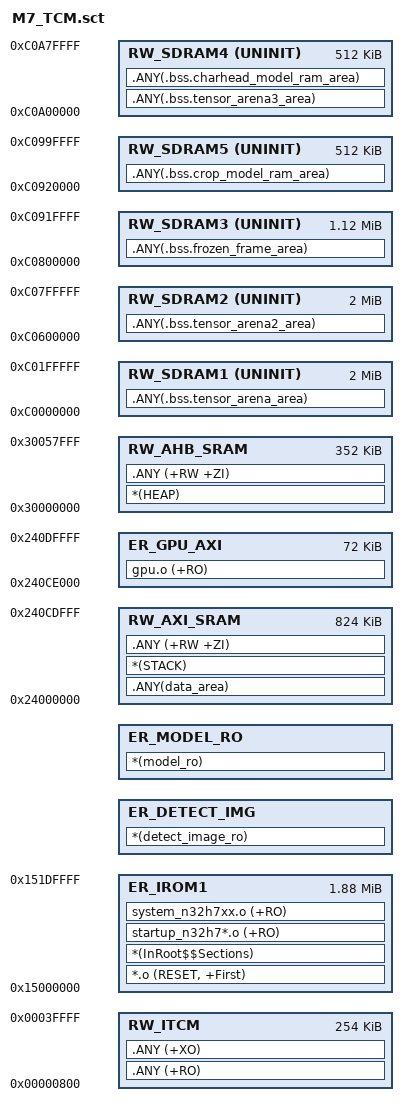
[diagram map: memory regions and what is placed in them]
; *************************************************************
; *** Scatter-Loading Description File generated by uVision ***
; *************************************************************
; N32H787xIx7:CM7 - WARNING: the ITCM / DTCM / AXI_SRAM2-3 split of the 1MB TCM
; block is NOT fixed hardware.  It is stored in OTP and selected by TCM_SIZE_VALUE
; in firmware\CMSIS\device\system_n32h7xx.c.  The value compiled in right now is:
;
;     #define TCM_SIZE_VALUE   (0x27)
;
; The table above ConfigTcmSize() (system_n32h7xx.c:113) has one row per value
; PER CHIP FAMILY, and 0x27 does not mean the same thing in two of them.  For
; N32H78x - this part - it is:
;
;     0x27 : 256 KB ITCM, 0 KB DTCM, 768 KB AXI_SRAM2/3, 128 KB AXI SRAM1
;
; while the N32H73x row for the same 0x27 says 384 KB of AXI_SRAM2/3.  An
; earlier version of this comment quoted the N32H73x row, which is where the
; 512K for RW_AXI_SRAM below used to come from - 384 KB short of what this part
; has, and the reason for the warning above.
;
; So the memory that physically exists with this setting is:
;   ITCM       0x00000000   256K   (vector table occupies 0x00000..0x007FF)
;   DTCM       0x20000000     0K   <-- DOES NOT EXIST, never place anything here
;   AXI SRAM   0x24000000   896K   (SRAM1 128K + SRAM2/3 768K)
;   AHB SRAM   0x30000000   352K   (0x30000000..0x30058000)
;   XIP flash  0x15000000  1.875M
;   SDRAM      0xC0000000    32M   (external, FEMC - the board is
;                                   SDRAM_IS42S32800J_HMI, AddrMask 0xFE000000.
;                                   The regions below claim 0xC0000000..0xC0B00000
;                                   only, which is deliberate; the camera's two
;                                   frame buffers and the GPU's slot sit inside
;                                   that span at raw addresses from inc/bsp_dvp.h
;                                   and inc/gpu.h.  The full map, and why the
;                                   bases are where they are, is written out at
;                                   RW_SDRAM1 near the end of this file)
;
; THE NUMBERS ABOVE ARE MEASURED ON THIS BOARD, not assumed.  They have to be
; measured, because that split is not fixed hardware: ConfigTcmSize()
; (system_n32h7xx.c:177) programs the OTP only when the register reads back
; 0x2C - i.e. never programmed - and it is written once per part, not per image.
; So a part that has run a vendor example first holds whatever that example
; asked for, and the 0x27 this build requests is then a silent no-op.  Nothing
; in a build says which way that went.
;
; gpu_tcm_probe() reads the OTP back at boot.  On 2026-09-15 it read
; 0x00000027, which is what the table above says this build asks for, so the
; two agree and the numbers above are the real ones.  That is what let
; RW_AXI_SRAM below grow from 512K to the full 896K.
;
; AHB SRAM is not one block either: it is AHBSRAM1..AHBSRAM5S2, six banks with
; independent power gates and retention controls (PWR_SYSMEMLPCTRL_AHBSRAM*_PG,
; *_RET1N, *_RET2N - n32h7xx.h:8302+).
;
;     0x30000000  SRAM1  128K   ┐
;     0x30020000  SRAM2  128K   ├ written every frame by the camera, so proven
;     0x30040000  SRAM3   32K   │ good on this board
;     0x30048000  SRAM4   32K   ┘
;     0x30050000  SRAM5b1 16K   ┐ nothing else on this board writes these
;     0x30054000  SRAM5b2 16K   ┘
;
; *(HEAP) is the reason this matters.  It used to start in SRAM4 and run out of
; SRAM5b2 - two banks nothing else on this board writes, which is a bad place to
; put the allocator on a board that has never proved them.  It now sits wholly
; inside SRAM1, the bank the camera writes every frame.
;
; Nothing below asks the hardware for that, and no line here says where the heap
; goes: it is a consequence of the globals no longer competing for
; RW_AHB_SRAM, so it is re-derived on every link.  After any change to either
; region, look it up in Printf.map and check it is still inside
; 0x30000000..0x30020000 - the map prints it as an unnamed
;
;     0x3000....        -       0x00008000   Zero   RW   2   HEAP  startup_n32h78x_cm7.o
;
; section (the label Heap_Mem is not exported, so only the section shows).
;
; Every vendor GPU example runs without complaint while using AHB SRAM for
; nothing but a small texture buffer at 0x30000000, keeping its heap in DTCM /
; AXI SRAM; this build keeps its C library heap in AHB SRAM instead, which is
; the one structural difference between the two.
;
; If TCM_SIZE_VALUE is ever changed, this file must change with it.
; armlink trusts the numbers below and cannot see the silicon: an over-sized
; region links cleanly with 0 errors and only faults on the board.
;
; History: a RW_DTCM 0x20000000 0x00080000 region was tried here and hung before
; main() - with TCM_SIZE_VALUE=0x27 DTCM is 0K, so the startup copy of the model
; and the stack went into unmapped space.

; Raised from 1MB to the part's full 1.875M (the header comment above).  1MB was
; 93.7% full: the map of the 2026-10-13 build reads
;
;     Load Region LR_IROM1 (Base: 0x15000000, Size: 0x000efd68, Max: 0x00100000
;
; 982,376 of 1,048,576 bytes - 66K free, and the two extra int8 models Phase 1
; adds are 431,360 + 90,144 = 521,504.  So this is not headroom, it is the
; change that makes ER_MODEL_RO placeable at all.
LR_IROM1 0x15000000 0x001E0000  {    ; load region size_region
  ; This Max only matches the load region; it is NOT the binding ceiling, and
  ; the earlier note in this file that called it one was wrong.  ER_IROM1 holds
  ; 0x2160 (8,544) bytes of vector table and startup code, and armlink places
  ; the next region after a region's *actual* size, not after its Max: the map
  ; above puts ER_DETECT_IMG at 0x15002160 = 0x15000000 + 0x2160.  Left at
  ; 0x00100000 this would link exactly the same.  Raised anyway, because a Max
  ; that does not mean what it looks like is a trap, and the day something does
  ; grow into ER_IROM1 the gap between these two lines surfaces as an L6220E
  ; naming the wrong region.
  ER_IROM1 0x15000000 0x001E0000  {  ; load address = execution address
   *.o (RESET, +First)
   *(InRoot$$Sections)
   startup_n32h7*.o (+RO)
   system_n32h7xx.o (+RO)
  }

  ; 320x320 RGB888 detection frame (src/yolo_detect_image.inc), 307,200 bytes,
  ; read in place out of XIP flash.  It must NOT be left to .ANY (+RO): that
  ; lands in ITCM, which only has ~117K free, so a 300K array would fail to
  ; place.  +0 puts it right after ER_IROM1 and ahead of the RW init copies, and
  ; armlink moves those up as needed.
  ER_DETECT_IMG +0  {
   *(detect_image_ro)
  }

  ; The ② crop detector and ③ char classifier int8 models (inc/model_data_crop.h
  ; and inc/model_data_charhead.h), 431,360 + 90,144 = 521,504 bytes.
  ;
  ; Stored here rather than in ①'s data_area because AXI SRAM has only ~114K
  ; spare once ① takes 431K of its 896K, and ② alone is 431,360 bytes.
  ;
  ; Read in place over the XIP bus was the original plan and is NOT what the
  ; firmware does: both are copied into SDRAM at init, with the D-cache off,
  ; and parsed from that copy.  The reason is the ② anomaly (one 32-byte row of
  ; the 431,360 read back as the file's bytes from +16); until its cause is
  ; known, the weights are not read out of flash at run time at all.  What this
  ; region decides is only where the bytes are *stored*, and both headers carry
  ; section("model_ro") - not ①'s section("data_area"), which __main copies to
  ; AXI SRAM before SDRAM exists.
  ;
  ; Placed with the detect image, before the RW init copies, so the model blobs
  ; sit together at the bottom of the flash.  This only picks the layout - what
  ; decides whether it fits is the load region above, 0x001E0000, and the weights
  ; are incompressible so armlink's compression saves almost nothing on them.
  ;
  ; Alignment: the arrays in here carry aligned(32) (see the ALIGN paragraph in
  ; tflite/export_c_array.py, and the long note above yolo_cascade_init() in
  ; MDK-ARM/yolo_inference.cpp), so armlink lifts this region's base to a 32-byte
  ; boundary.  It used to sit at 0x1504d110 - 16-aligned, not 32 - and the only
  ; wrong bytes the board ever read out of the 431,360 were exactly the first
  ; full 32-byte line of it.  Check the new address in Printf.map after linking.
  ER_MODEL_RO +0  {
   *(model_ro)
  }

  ;ITCM 256K, offset 0x400 for VECTOR TABLE
  RW_ITCM 0x00000800 0x0003F800  {
   .ANY (+RO)
   .ANY (+XO)
  }

  ; AXI SRAM 0x24000000 + 896K, which is everything the part has under 0x27
  ; (AXI_SRAM1 0x24000000 128K + AXI_SRAM2 0x24020000 512K + AXI_SRAM3
  ; 0x240A0000 256K, from n32h7xx_eccmon.h:81-83, contiguous).  It was 512K
  ; until gpu_tcm_probe() read the OTP back and confirmed 0x27 on this board;
  ; see the header comment.
  ;
  ; Holds everything that is not read-only: the 431KB yolo int8 model - __main
  ; copies it out of XIP flash at startup, so nothing reads the weights over the
  ; XIP bus at run time any more - the main stack, and now the RW/ZI globals too.
  ;
  ; .ANY (+RW +ZI) was commented out while the region was 512K, because
  ; 431,360 (model) + 65,536 (stack) = 496,896 left only ~27K and the rest had
  ; to go somewhere.  That is why ~337K of this firmware's state ended up in
  ; AHB SRAM, pressed right up against the C library heap - and an overrunning
  ; global there silently corrupts the allocator instead of failing loudly,
  ; which is what cost a long session on the GPU bring-up.  With the full 896K
  ; the globals fit here and that pressure is gone.  What still lands in AHB
  ; SRAM is a few KB at the bottom of the region; the heap sits ~5K above it
  ; and is no longer the neighbour of anything large.
  ;
  ; Max is 0x000CE000, not the full 0x000E0000: the top 0x12000 (72 KB) is
  ; handed to ER_GPU_AXI just below, which is what makes GPU_ENABLE=1 link
  ; again.  Shrinking Max does not move the base, and armlink's .ANY choice
  ; does not depend on Max, so nothing in this region should have moved - but
  ; check it: the map's RW_AXI_SRAM Size must still read 0x000c4500 (803,072,
  ; measured 2026-10-16).  If it changed, something got pushed into AHB SRAM.
  RW_AXI_SRAM 0x24000000 0x000CE000  {
   .ANY(data_area)
   *(STACK)
   .ANY (+RW +ZI)
  }

  ; ---------------------------------------------------------------------------
  ; gpu.c's read-only content - its code and its own rodata, 33,157 bytes
  ; (Code 27,648 + RO 5,509, the Image component sizes table in Printf.map).
  ; It lives in AXI SRAM rather than ITCM so that GPU_ENABLE=1 and the
  ; three-network cascade can be in one image.
  ;
  ; THE PROBLEM IT SOLVES.  Turning GPU_ENABLE back on on 2026-10-16 failed to
  ; link: 484 x L6406E, every one of them a read-only section, zero RW/ZI - so
  ; exactly one execution region was full, and the only region in this file
  ; that takes .text/.rodata at all is RW_ITCM's `.ANY (+RO)` above.  Measured
  ; by relinking with that region's Max inflated: RW_ITCM needs 0x40500
  ; (263,424) and has 0x3F800 (260,096) - short by 3,328 bytes.  Nothing else
  ; is close: flash has 424 KB spare, RW_AXI_SRAM 111 KB, RW_AHB_SRAM 191 KB.
  ; Both halves of that were in the budget already: the GPU build needed
  ; ~237,388 of ITCM and had ~22.7 KB spare before the cascade, and the
  ; cascade adds 26,036 (Code +21,072, rodata +4,964).
  ;
  ; WHY AXI SRAM AND NOT XIP FLASH.  XIP is the obvious home for "cold" code -
  ; ER_DETECT_IMG right above reads in place out of it - but it is also the
  ; read path that returned one 32-byte row of ②'s weights wrong, and whose
  ; cause is still open (see the RW_SDRAM5 block and the note above
  ; yolo_cascade_init()).  A wrong *pixel* is one wrong character; a wrong
  ; *instruction fetch* is a board that runs off into nothing.  AXI SRAM is
  ; internal, the same reliability class as ITCM, I-cached like anything else,
  ; and 0x240CE000 is already inside the SRAM3 territory RW_AXI_SRAM has been
  ; using up to 0x240C4500 for a day.
  ;
  ; WHY ONLY gpu.o.  It is the largest item that is ours to move (33,157) and
  ; the shortfall is 3,328.  The DAVE HD driver stays in ITCM: it comes out of
  ; nsgpu.lib, and naming a library member in a scatter region force-extracts
  ; it, so moving it would drag the whole kernel into builds that do not
  ; reference it.  gpu.o is an ordinary object file, and an explicit selector
  ; for a *removed* section does not bring it back - measured 2026-10-16 with
  ; mock_micro_graph.o, which stayed removed and left the image byte-identical.
  ;
  ; WHAT THAT MEANS AT GPU_ENABLE=0.  The region's selector matches only
  ; sections that --remove has already dropped, so armlink reports
  ;
  ;     Warning: L6329W: Pattern gpu.o(RO) only matches removed unused sections.
  ;
  ; and the image is exactly what it was before this region existed.  That
  ; warning is expected in a GPU_ENABLE=0 build, not a symptom.  It is the one
  ; build-time trace of a region that exists to serve the other build.
  ;
  ; Nothing needs an MPU region for this.  main.c programs regions 0/1/3/4/5,
  ; all in SDRAM, and calls MPU_Enable(MPU_PRIVILEGED_DEFAULT) - so this falls
  ; back to the default memory map, which marks 0x20000000..0x3FFFFFFF Normal,
  ; cacheable and executable.  That is the same reason the rest of AXI SRAM
  ; (the stack, the globals) works without a region of its own.
  ; ---------------------------------------------------------------------------
  ER_GPU_AXI 0x240CE000 0x00012000  {
   gpu.o (+RO)
  }

  ; AHB SRAM 0x30000000 + 352K - the spillover region, and the home of the C
  ; library heap.  Most of it is now unused: RW_AXI_SRAM above took the globals,
  ; so this holds *(HEAP) plus the few KB of sections armlink's .ANY placement
  ; chose to put here.  That is fine - the point of the change is which bank the
  ; heap lands in, not how full this region is; see the header comment.
  RW_AHB_SRAM 0x30000000 0x00058000  {
   *(HEAP)
   .ANY (+RW +ZI)
  }

  ; yolo-320 int8: tensor arena -> external SDRAM 0xC0000000 (FEMC).
  ; UNINIT: SDRAM not ready during startup, so it must NOT be zero-initialised.
  ; The section is emitted as ZI (SHT_NOBITS) only because its name starts with
  ; ".bss." (Arm Compiler 6); a plain name would become RW and get copied by
  ; __main before SDRAM init -> HardFault before main.
  ;
  ; 2MB, not the full 8MB: the camera needs TWO 800x480 RGB565 frame buffers and
  ; there is no SRAM big enough for even one, so everything above the arena is
  ; handed to it at CAM_FRAME_BUFFER_ADDRESS / CAM_FRAME_BUFFER2_ADDRESS =
  ; 0xC0200000 / 0xC02BB800 (inc/bsp_dvp.h).  The two numbers are one decision -
  ; changing either means changing both.
  ;
  ; 2MB is not a guess: yolo_plate_init() prints arena_used_bytes() and the board
  ; reports 1,303,080 bytes used, so this leaves ~790KB spare.  It was 7.25MB
  ; while there was only one frame buffer; the second one is what bought the
  ; shrink (one frame buffer does not fit in the 30KB that was left over).
  ;
  ; RW_SDRAM2/3/4 at the end of this file continue this layout; read the block
  ; comment there before moving anything.
  RW_SDRAM1 0xC0000000 UNINIT 0x00200000  {  ; 2 MB tensor arena
   .ANY(.bss.tensor_arena_area)
  }

  ; ---------------------------------------------------------------------------
  ; The rest of SDRAM, 0xC0200000 up to 0xC0C00000.  It is one decision spread
  ; over four files - this one, inc/bsp_dvp.h, inc/gpu.h and the MPU table in
  ; src/main.c - so the whole layout is written out here.  Nothing allocates;
  ; every address is raw:
  ;
  ;   0xC0000000  RW_SDRAM1          2MB    ① tensor arena            (here)
  ;   0xC0200000  CAM_FRAME_BUFFER         800x480 RGB565, ping-pong   (bsp_dvp.h)
  ;   0xC02BB800  CAM_FRAME_BUFFER2        second half of that pair
  ;   0xC0377000  <- the two frame buffers end here (src/camera.c:512 agrees;
  ;                  the 0xC0371000 in src/main.c's region-1 comment does not,
  ;                  it is a digit short - 2 x 768,000 = 0x177000)
  ;   0xC0380000  CAM_ALT_BUF
  ;   0xC03D0000  <- crop_fill_neigh() paints 192K up to here (gpu.c:3586)
  ;   0xC0400000  GPU_CROP_SRC             GPU crop source            (gpu.h)
  ;   0xC04BB800  <- same function paints 264K from here, i.e. from
  ;                  CROP_SRC + CROP_PITCH*CROP_PROD_H*2 = +800*480*2 (gpu.c:3587)
  ;   0xC053F800  <- and ends here.  This is the highest address any GPU crop
  ;                  write reaches; everything between it and 0xC0C00000 is free
  ;   0xC0600000  RW_SDRAM2          2MB    ② tensor arena            (here)
  ;   0xC0800000  RW_SDRAM3       1.099MB  frozen 800x480 RGB888 frame (here)
  ;   0xC0A00000  RW_SDRAM4        512K    ③ arena + weight copy     (here)
  ;   0xC0C00000  GPU_SLOT_BASE       4MB    GPU slot                  (gpu.h)
  ;   0xC0E00000  GPU_DW_SRC / 0xC0FC0000 GPU_SCALE_DST
  ;
  ; Every base below is a multiple of 2MB, and that is not tidiness.  An MPU
  ; region must be a power of two long and aligned to its own length, so a 2MB
  ; region can only start at 0xC0600000, 0xC0800000 or 0xC0A00000.  The frame
  ; buffers and 0xC053F800 are not usable bases at all, which is what puts the
  ; first of the three 786K past the GPU crop's high-water mark rather than
  ; wherever it would be tidier to start.
  ;
  ; None of them may reach 0xC0C00000 either.  src/main.c makes these regions
  ; cacheable, and 0xC0C00000-on must stay uncacheable Device memory: make the
  ; GPU slot cacheable and CPU writes to GPU_CROP_SRC sit in the D-cache while
  ; the GPU DMAs memory, so the next read returns stale pixels - and this board
  ; has no cache maintenance call to fix that mid-transfer.  That is the whole
  ; reason there are three regions here and not one 8MB region at 0xC0400000.
  ;
  ; UNINIT on all three, like RW_SDRAM1: SDRAM is not ready during startup and
  ; must not be zero-initialised or copied into.  Each section name starts with
  ; ".bss." so Arm Compiler 6 emits it as ZI/SHT_NOBITS; a plain name makes it
  ; RW, and __main then copies it before SDRAM init -> HardFault before main().
  ; ---------------------------------------------------------------------------

  ; ② tensor arena.  2MB for the same reason RW_SDRAM1 is 2MB: ② has ①'s exact
  ; architecture - same 85-channel layout, same two heads, same 20x20 + 10x10
  ; grids - so it needs the same arena, and ① measured 1,303,080 bytes used.
  ; 1.5MB would do; 2MB costs nothing here and keeps the two regions identical
  ; to reason about.
  RW_SDRAM2 0xC0600000 UNINIT 0x00200000  {
   .ANY(.bss.tensor_arena2_area)
  }

  ; The frozen full-resolution camera frame: 800x480 RGB888 = 1,152,000 =
  ; 0x119400 bytes, rounded up to 0x120000.  (Not 1,125,000 - that arithmetic
  ; slip is 25,600 bytes short and would have failed as an L6220E.)
  ;
  ; src/main.c's MPU region 4 covers this with a 2 MB region, which is the only
  ; size an MPU region starting at 0xC0800000 can be.  The region is therefore
  ; 0xC0800000..0xC09FFFFF and the 0xAC000 of slack here is unusable by anything
  ; else - do not move RW_SDRAM4 down into it.
  ;
  ; Freezing the frame is required, not an optimisation.  The ping-pong buffers
  ; flip every ~66ms while one 320x320 inference takes 1.7-4.6s, so ② calling
  ; camera_frame_addr() again would crop a different picture than the one ①'s
  ; box came from - a silent, plausible-looking wrong answer.  The address is
  ; pinned once, unpacked here, and ②/③ derive from this copy only.
  RW_SDRAM3 0xC0800000 UNINIT 0x00120000  {
   .ANY(.bss.frozen_frame_area)
  }

  ; ② 的模型副本: XIP flash 里的 g_model_crop 拷进来的那份 (见
  ; MDK-ARM/yolo_inference.cpp 里 yolo_cascade_init() 顶上那段长的)。
  ;
  ; 为什么需要它: 上板在 TFLM 的 StartModelAllocation 里崩了, 反汇编钉到
  ; `LDRH r1,[vtable,#8]` 读回了 0xEA2C —— 而文件里那个位置是 20 (根表才 32
  ; 字节, 合法字段偏移到不了 59948)。 也就是 ② 从 XIP 读到的字节和文件不是同一份。
  ; 2026-10-16 量出来的形状: 板子读到的 431,360 字节和文件只差**一条 32 字节
  ; 行** (rel 0x10..0x2F), 装的是文件 +16 处的内容; 而磁盘上那个镜像逐字节
  ; 是对的 (tflite/_dbg_image.py 比过), 也不是读宽度 (32/16/8 位四个 CRC 全等)。
  ; 所以先按 ① 的办法办, 只是目的地换成 SDRAM; 而且拷贝那一遍放在关掉 D-Cache 的
  ; 区间里做 —— 关着读和开着读的 CRC32 都打出来, 这一对数就是
  ; "CPU 读通路" 和 "flash 内容不对" 的分界。 详见 yolo_cascade_init() 顶上那段。
  ;
  ; 0xC0920000 = RW_SDRAM3 的 Max 末尾 (0xC0800000 + 0x120000), 所以它既在
  ; MPU region 4 (0xC0800000, 2MB, WB cacheable) 里, 又不和冻结帧抢地盘;
  ; 431,360 字节 = 0x69500 到这里 0x80000 的余量还有 0x16B00。
  ; 上面那段注释说这 0xAC000 "unusable by anything else", 那是指没人给它声明
  ; 过 exec 区 —— 现在声明了, 它就是可用的 SDRAM, 不是别的东西的地盘。
  RW_SDRAM5 0xC0920000 UNINIT 0x00080000  {
   .ANY(.bss.crop_model_ram_area)
  }

  ; ③ tensor arena + ③'s SDRAM copy of its weights.
  ;
  ; ③ is a 4-conv classifier: 90,144 bytes of weights, a 32x64 input, a global
  ; average pool.  Its largest tensor is the first conv's 64x32x16 = 32 KB, so
  ; 256K is already generous for the arena and the other 96K holds the weights.
  ; 512K in total, still clearing 0xC0C00000 with 1.5MB to spare.
  ;
  ; Why a copy when the weights could be read in place out of XIP flash: ② had
  ; exactly one 32-byte row read back wrong out of 431,360, and this build is
  ; the one that measures the remedy (32-byte alignment + a copy taken with the
  ; D-cache off) rather than assuming it.  ③ sits immediately after ② in flash,
  ; on the same read path, and one wrong row there would show up as "a couple
  ; of characters recognised wrong" - the hardest kind of error to spot from a
  ; live picture.  96K of SDRAM and one 90 KB memcpy at init is cheap until the
  ; root cause of the ② anomaly is known.
  ;
  ; Both section names must start with ".bss." for the same reason as every
  ; other buffer in this file: the prefix is what makes armclang emit
  ; SHT_NOBITS, and a PROGBITS section here would be copied by __main before
  ; SDRAM exists - HardFault before main(), not one character on the UART.
  RW_SDRAM4 0xC0A00000 UNINIT 0x00080000  {
   .ANY(.bss.tensor_arena3_area)
   .ANY(.bss.charhead_model_ram_area)
  }
}

